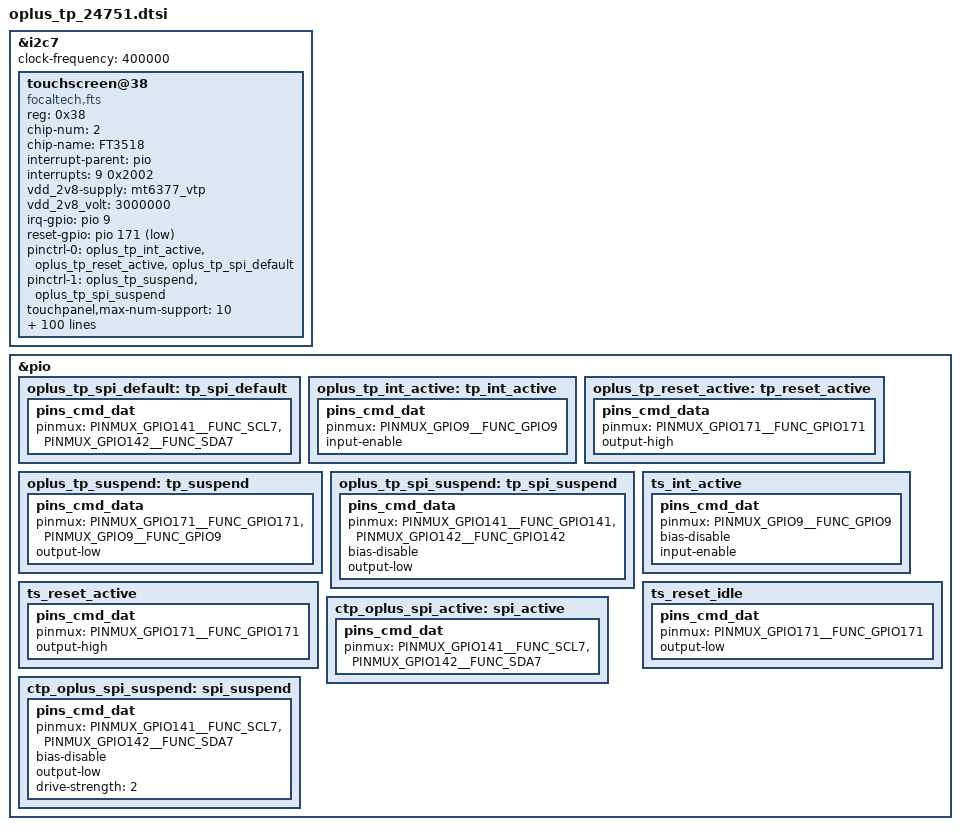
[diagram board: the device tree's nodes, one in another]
&i2c7 {
    status = "okay";
    #address-cells = <1>;
    #size-cells = <0>;
    clock-frequency = <400000>;

    touchscreen@38{
        status = "okay";
        compatible = "focaltech,fts";
        reg = <0x38>;
        chip-num = <2>;
        chip-name = "FT3518";

        //spi-max-frequency = <12000000>;
        /* Interrupt && Irq-gpio */
        interrupt-parent = <&pio>;
        interrupts = <9 0x2002>;

        /* Power Config */
        vdd_2v8-supply  = <&mt6377_vtp>;
        vdd_2v8_volt = <3000000>;
        //enable1v8_gpio = <&pio 22 0x1>;
        //vcc_1v8-supply  = <&mt6369_vtp>;
        //vcc_1v8_volt = <1800000>;

        /* Other HW Resource */

        irq-gpio = <&pio 9 0x2002>;
        reset-gpio = <&pio 171 0x1>;

        pinctrl-names = "default",  "sleep";
        pinctrl-0 = <&oplus_tp_int_active &oplus_tp_reset_active &oplus_tp_spi_default>;
        pinctrl-1 = <&oplus_tp_suspend &oplus_tp_spi_suspend>;

        touchpanel,max-num-support = <10>;
        touchpanel,tx-rx-num = <16 34>;
        touchpanel,panel-coords = <8640 19200>;
        touchpanel,display-coords = <1080 2400>;
        touchpanel,touchmajor-limit = <0 54>;
        touchpanel,smooth-level = <255 15 40 80 160 240>;
        touchpanel,sensitive-level = <255 30 25 20 10 8>;
        touchpanel,high-frame-rate-time = <20>;
        touchpanel,single-optimized-time = <8>;
        touchpanel,aiunit_game_valid_bits = <19>;

        panel_type = <8>;
        firmware_name = "0xAC116F00";
        platform_support_project = <24751 24752 24782>;
        platform_support_project_dir = <24751 24751 24751>;
        platform_support_project_commandline = "default_commandline","default_commandline","default_commandline";

        prevention,curved_screen_V2;
        prevention,grip_disable_level = <6>;
        prevention,updelay_time_ms = <30>;
        prevention,makeup_cnt_weight = <4 1 2 2 2>;
        prevention,large_corner_range = <960 2400>;
        prevention,large_corner_judge_condition = <500 300 800 7 7>;
        prevention,trx_reject_condition = <9 6 7>;
        prevention,trx_strict_reject_condition = <8 5 6>;
        prevention,large_judge_time_ms = <500 50 30>;
        prevention,large_exit_condition = <8 8 2>;
        prevention,single_channel_width = <160 160>;
        prevention,normal_tap_condition = <10 350>;
        prevention,long_edge_condition = <200 80 180 80>;
        prevention,long_strict_edge_condition = <160 60>;
        prevention,long_fingerhold_condition = <50 6 4 4>;
        prevention,short_edge_condition = <200 80 180 80>;
        prevention,short_strict_edge_condition = <160 60>;
        prevention,large_strict_exit_condition = <4 4>;
        prevention,top_corner_config = <440 1200 360>;
        prevention,edge_swipe_config = <240 960>;

        prevention,curved_screen_V4;
        prevention,long_eliminate_point_type = <2 8640 6400 240 19200 300 1>;
        prevention,long_fingerhold_condition2 = <420 0 0 0>;
        prevention,top_corner_config2 = <3 80 480 0 0>;
        prevention,hor_long_top_corner_config = <240 1600 0 0>;
        prevention,top_middle_config = <8640 800 800 0>;
        prevention,corner_eliminate_point_type = <0 960 1600 1>;
        prevention,finger_hold_differ_size = <1 0 240 300>;
        prevention,finger_hold_max_rx_exit_distance = <5 240 1600>;
        prevention,max_rx_exit_distance = <1 5 150 240 1600>;
        prevention,dynamic_finger_hold_exit_distance = <1 240 1600 360>;
        prevention,edge_sliding_matched_support = <1 150 3 0>;
        //grip v4.2 reclining mode
        prevention,reclining_mode_support = <1>;
        prevention,long_eliminate_point_type_recli = <2 8640 6400 240 19200 500 0>;
        prevention,finger_hold_differ_size_recli = <1 0 240 400>;
        prevention,finger_hold_max_rx_exit_distance_recli = <4 240 1600>;
        prevention,max_rx_exit_distance_recli = <1 4 100 240 1600>;
        prevention,dynamic_finger_hold_exit_distance_recli = <1 240 1600 360>;
        prevention,edge_sliding_matched_support_recli = <1 200 3 0>;
        prevention,long_edge_condition_recli = <160 80 120 80>;

        /* SW Support Feature Control */
        black_gesture_support;
        black_gesture_indep_support;
        sportify_aod_gesture_support;
        pressure_report_support;
        charger_pump_support;
        game_switch_support;
        smart_gesture_support;
        fw_update_app_support;
        fingerprint_underscreen_support;
        screenoff_fingerprint_info_support;
        irq_need_dev_resume_ok;
        kernel_grip_support;
        //fw_edge_limit_support;
        exception_upload_support;
        health_monitor_support;
        //focalt x8 resolution config
        high_resolution_support;
        high_resolution_support_x8;
        disable_suspend_irq_handler_support;
        palm_to_sleep_support;
        snr_read_support;
        esd_handle_support;
        fingerprint_not_report_in_suspend;
        diaphragm_touch_support;
        report_rate_white_list_support;
        aiunit_game_info_support;
        /*
            *Virtual Key Config:
            *1:touchpanel,button-type: <virtualkey_type  supportted_button-map>
            *virtualkey_type:
            *Type 1: using board_properties
            *Type 2: using same IC (button zone&& touch zone are seprate)
            *Type 3: using diffrent IC (button zone&& touch zone are seprate)
            *Type 4: No need of virtual key process
            *supportted_button-map:select|menu|home|back
            *
            *2:touchpanel,button-map
            *type (X1,Y1)(X2,Y2)(X3,Y3)(Width_X,Hight_Y)--Only when button-type is 0
        */
        touchpanel,button-type = <4>;
        touchpanel.button-TRx = <0 0>;
    };
};

&pio {
    oplus_tp_spi_default: tp_spi_default {
        pins_cmd_dat {
            pinmux = <PINMUX_GPIO141__FUNC_SCL7>,
                     <PINMUX_GPIO142__FUNC_SDA7>;
        };
    };

    oplus_tp_int_active: tp_int_active {
        pins_cmd_dat {
            pinmux = <PINMUX_GPIO9__FUNC_GPIO9>;
            input-enable;
        };
    };
    oplus_tp_reset_active: tp_reset_active {
        pins_cmd_data {
            pinmux = <PINMUX_GPIO171__FUNC_GPIO171>;
            output-high;
        };
    };
    oplus_tp_suspend: tp_suspend {
        pins_cmd_data {
            pinmux = <PINMUX_GPIO171__FUNC_GPIO171>,
                    <PINMUX_GPIO9__FUNC_GPIO9>;
            output-low;
        };
    };
    oplus_tp_spi_suspend: tp_spi_suspend {
        pins_cmd_data {
            pinmux = <PINMUX_GPIO141__FUNC_GPIO141>,
                    <PINMUX_GPIO142__FUNC_GPIO142>;
            bias-disable;
            output-low;
        };
    };

    /*add for DF-25 TP*/
    ts_int_active: ts_int_active {
        pins_cmd_dat {
            pinmux = <PINMUX_GPIO9__FUNC_GPIO9>;
            bias-disable;
            input-enable;
        };
    };
    ts_reset_active: ts_reset_active {
        pins_cmd_dat {
            pinmux = <PINMUX_GPIO171__FUNC_GPIO171>;
            output-high;
        };
    };
    ts_reset_idle: ts_reset_idle {
        pins_cmd_dat {
            pinmux = <PINMUX_GPIO171__FUNC_GPIO171>;
            output-low;
        };
    };
    ctp_oplus_spi_active: spi_active {
        pins_cmd_dat {
            pinmux = <PINMUX_GPIO141__FUNC_SCL7>,
                     <PINMUX_GPIO142__FUNC_SDA7>;
        };
    };
    ctp_oplus_spi_suspend: spi_suspend {
        pins_cmd_dat {
            pinmux = <PINMUX_GPIO141__FUNC_SCL7>,
                     <PINMUX_GPIO142__FUNC_SDA7>;
            bias-disable;
            output-low;
            drive-strength = <2>;
        };
    };

};
